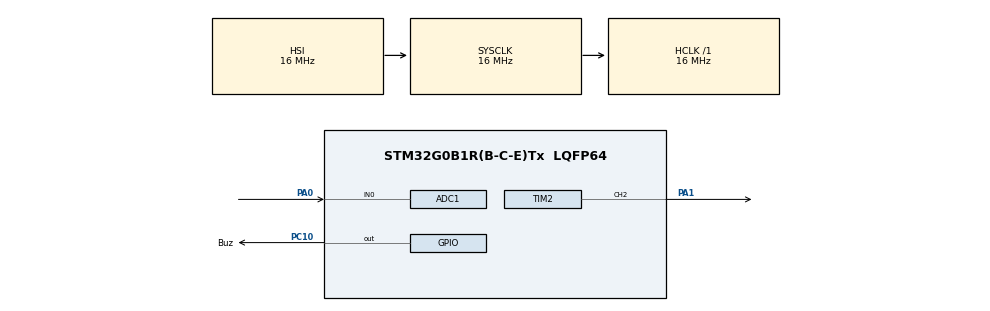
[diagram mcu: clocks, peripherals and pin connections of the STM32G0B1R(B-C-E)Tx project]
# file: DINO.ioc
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ADC1.Channel-0\#ChannelRegularConversion=ADC_CHANNEL_0
ADC1.ContinuousConvMode=ENABLE
ADC1.NbrOfConversionFlag=1
ADC1.Rank-0\#ChannelRegularConversion=1
ADC1.Resolution=ADC_RESOLUTION_6B
ADC1.SamplingTime-0\#ChannelRegularConversion=ADC_SAMPLINGTIME_COMMON_1
ADC1.SamplingTimeCommon1=ADC_SAMPLETIME_1CYCLE_5
ADC1.SamplingTimeCommon2=ADC_SAMPLETIME_1CYCLE_5
ADC1.SelectedChannel=ADC_CHANNEL_0
ADC1.master=1
Mcu.Family=STM32G0
Mcu.Name=STM32G0B1R(B-C-E)Tx
Mcu.Package=LQFP64
PA0.Mode=IN0
PA0.Signal=ADC1_IN0
PA1.Signal=S_TIM2_CH2
PA13.Mode=Serial_Wire
PA13.Signal=SYS_SWDIO
PA14-BOOT0.Mode=Serial_Wire
PA14-BOOT0.Signal=SYS_SWCLK
PC10.GPIO_Label=Buz
PC10.Signal=GPIO_Output
ProjectManager.HeapSize=0x200
ProjectManager.StackSize=0x400
ProjectManager.TargetToolchain=STM32CubeIDE
RCC.AHBFreq_Value=16000000
RCC.CortexFreq_Value=16000000
RCC.EXTERNAL_CLOCK_VALUE=48000
RCC.HCLKFreq_Value=16000000
RCC.HSE_VALUE=8000000
RCC.HSI48_VALUE=48000000
RCC.HSI_VALUE=16000000
RCC.LSE_VALUE=32768
RCC.SYSCLKFreq_VALUE=16000000
RCC.USBFreq_Value=48000000
RCC.VCOOutputFreq_Value=128000000
SH.S_TIM2_CH2.0=TIM2_CH2,PWM Generation2 CH2
TIM2.Channel-PWM\ Generation2\ CH2=TIM_CHANNEL_2
TIM2.Period=1000
TIM2.Prescaler=64
VP_SYS_VS_DBSignals.Mode=DisableDeadBatterySignals
VP_TIM2_VS_ClockSourceINT.Mode=Internal
board=custom

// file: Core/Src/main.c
/* USER CODE BEGIN Header */
/**
  ******************************************************************************
  * @file           : main.c
  * @brief          : Main program body
  ******************************************************************************
  * @attention
  *
  * Copyright (c) 2022 STMicroelectronics.
  * All rights reserved.
  *
  * This software is licensed under terms that can be found in the LICENSE file
  * in the root directory of this software component.
  * If no LICENSE file comes with this software, it is provided AS-IS.
  *
  ******************************************************************************
  */
/* USER CODE END Header */
#include "main.h"

/* USER CODE BEGIN Includes */
#include<stdint.h>
/* USER CODE END Includes */

/* USER CODE BEGIN PTD */
	uint32_t ldr = 0, timer = 0;
	uint8_t flag = 0;
/* USER CODE END PTD */

ADC_HandleTypeDef hadc1;

TIM_HandleTypeDef htim2;

void SystemClock_Config(void);
static void MX_GPIO_Init(void);
static void MX_ADC1_Init(void);
static void MX_TIM2_Init(void);

int main(void)
{

  /* MCU Configuration--------------------------------------------------------*/

  /* Reset of all peripherals, Initializes the Flash interface and the Systick. */
  HAL_Init();

  /* Configure the system clock */
  SystemClock_Config();

  /* Initialize all configured peripherals */
  MX_GPIO_Init();
  MX_ADC1_Init();
  MX_TIM2_Init();
  /* USER CODE BEGIN 2 */
  HAL_TIM_PWM_Start(&htim2, TIM_CHANNEL_2);//inicializa pwm que controla servo;
  TIM2->CCR2 = 65;

  /* USER CODE END 2 */

  /* Infinite loop */
  /* USER CODE BEGIN WHILE */
  while (1)
  {
    //leitura do LDR por ADC;
		HAL_ADC_Start(&hadc1);
		HAL_ADC_PollForConversion(&hadc1, 1);
		ldr = HAL_ADC_GetValue(&hadc1);

    //se identificar obstaculo ativa o servo;
		if (ldr > 8) {
			HAL_GPIO_WritePin(Buz_GPIO_Port, Buz_Pin, GPIO_PIN_SET);
			TIM2->CCR2 = 300;//define a posição do servo;
		}else{
			HAL_GPIO_WritePin(Buz_GPIO_Port, Buz_Pin, GPIO_PIN_RESET);
			TIM2->CCR2 = 500;//define a posição do servo;
		}

    /* USER CODE END WHILE */

    /* USER CODE BEGIN 3 */

	HAL_Delay(10);

  }
  /* USER CODE END 3 */
}

void SystemClock_Config(void)
{
  RCC_OscInitTypeDef RCC_OscInitStruct = {0};
  RCC_ClkInitTypeDef RCC_ClkInitStruct = {0};

  /** Configure the main internal regulator output voltage
  */
  HAL_PWREx_ControlVoltageScaling(PWR_REGULATOR_VOLTAGE_SCALE1);
  /** Initializes the RCC Oscillators according to the specified parameters
  * in the RCC_OscInitTypeDef structure.
  */
  RCC_OscInitStruct.OscillatorType = RCC_OSCILLATORTYPE_HSI;
  RCC_OscInitStruct.HSIState = RCC_HSI_ON;
  RCC_OscInitStruct.HSIDiv = RCC_HSI_DIV1;
  RCC_OscInitStruct.HSICalibrationValue = RCC_HSICALIBRATION_DEFAULT;
  RCC_OscInitStruct.PLL.PLLState = RCC_PLL_NONE;
  if (HAL_RCC_OscConfig(&RCC_OscInitStruct) != HAL_OK)
  {
    Error_Handler();
  }
  /** Initializes the CPU, AHB and APB buses clocks
  */
  RCC_ClkInitStruct.ClockType = RCC_CLOCKTYPE_HCLK|RCC_CLOCKTYPE_SYSCLK
                              |RCC_CLOCKTYPE_PCLK1;
  RCC_ClkInitStruct.SYSCLKSource = RCC_SYSCLKSOURCE_HSI;
  RCC_ClkInitStruct.AHBCLKDivider = RCC_SYSCLK_DIV1;
  RCC_ClkInitStruct.APB1CLKDivider = RCC_HCLK_DIV1;

  if (HAL_RCC_ClockConfig(&RCC_ClkInitStruct, FLASH_LATENCY_0) != HAL_OK)
  {
    Error_Handler();
  }
}

static void MX_ADC1_Init(void)
{

  ADC_ChannelConfTypeDef sConfig = {0};

  /** Configure the global features of the ADC (Clock, Resolution, Data Alignment and number of conversion)
  */
  hadc1.Instance = ADC1;
  hadc1.Init.ClockPrescaler = ADC_CLOCK_SYNC_PCLK_DIV2;
  hadc1.Init.Resolution = ADC_RESOLUTION_6B;
  hadc1.Init.DataAlign = ADC_DATAALIGN_RIGHT;
  hadc1.Init.ScanConvMode = ADC_SCAN_DISABLE;
  hadc1.Init.EOCSelection = ADC_EOC_SINGLE_CONV;
  hadc1.Init.LowPowerAutoWait = DISABLE;
  hadc1.Init.LowPowerAutoPowerOff = DISABLE;
  hadc1.Init.ContinuousConvMode = ENABLE;
  hadc1.Init.NbrOfConversion = 1;
  hadc1.Init.DiscontinuousConvMode = DISABLE;
  hadc1.Init.ExternalTrigConv = ADC_SOFTWARE_START;
  hadc1.Init.ExternalTrigConvEdge = ADC_EXTERNALTRIGCONVEDGE_NONE;
  hadc1.Init.DMAContinuousRequests = DISABLE;
  hadc1.Init.Overrun = ADC_OVR_DATA_PRESERVED;
  hadc1.Init.SamplingTimeCommon1 = ADC_SAMPLETIME_1CYCLE_5;
  hadc1.Init.SamplingTimeCommon2 = ADC_SAMPLETIME_1CYCLE_5;
  hadc1.Init.OversamplingMode = DISABLE;
  hadc1.Init.TriggerFrequencyMode = ADC_TRIGGER_FREQ_HIGH;
  if (HAL_ADC_Init(&hadc1) != HAL_OK)
  {
    Error_Handler();
  }
  /** Configure Regular Channel
  */
  sConfig.Channel = ADC_CHANNEL_0;
  sConfig.Rank = ADC_REGULAR_RANK_1;
  sConfig.SamplingTime = ADC_SAMPLINGTIME_COMMON_1;
  if (HAL_ADC_ConfigChannel(&hadc1, &sConfig) != HAL_OK)
  {
    Error_Handler();
  }

}

static void MX_TIM2_Init(void)
{

  TIM_ClockConfigTypeDef sClockSourceConfig = {0};
  TIM_MasterConfigTypeDef sMasterConfig = {0};
  TIM_OC_InitTypeDef sConfigOC = {0};

  htim2.Instance = TIM2;
  htim2.Init.Prescaler = 64;
  htim2.Init.CounterMode = TIM_COUNTERMODE_UP;
  htim2.Init.Period = 1000;
  htim2.Init.ClockDivision = TIM_CLOCKDIVISION_DIV1;
  htim2.Init.AutoReloadPreload = TIM_AUTORELOAD_PRELOAD_DISABLE;
  if (HAL_TIM_Base_Init(&htim2) != HAL_OK)
  {
    Error_Handler();
  }
  sClockSourceConfig.ClockSource = TIM_CLOCKSOURCE_INTERNAL;
  if (HAL_TIM_ConfigClockSource(&htim2, &sClockSourceConfig) != HAL_OK)
  {
    Error_Handler();
  }
  if (HAL_TIM_PWM_Init(&htim2) != HAL_OK)
  {
    Error_Handler();
  }
  sMasterConfig.MasterOutputTrigger = TIM_TRGO_RESET;
  sMasterConfig.MasterSlaveMode = TIM_MASTERSLAVEMODE_DISABLE;
  if (HAL_TIMEx_MasterConfigSynchronization(&htim2, &sMasterConfig) != HAL_OK)
  {
    Error_Handler();
  }
  sConfigOC.OCMode = TIM_OCMODE_PWM1;
  sConfigOC.Pulse = 0;
  sConfigOC.OCPolarity = TIM_OCPOLARITY_HIGH;
  sConfigOC.OCFastMode = TIM_OCFAST_DISABLE;
  if (HAL_TIM_PWM_ConfigChannel(&htim2, &sConfigOC, TIM_CHANNEL_2) != HAL_OK)
  {
    Error_Handler();
  }
  HAL_TIM_MspPostInit(&htim2);

}

static void MX_GPIO_Init(void)
{
  GPIO_InitTypeDef GPIO_InitStruct = {0};

  /* GPIO Ports Clock Enable */
  __HAL_RCC_GPIOA_CLK_ENABLE();
  __HAL_RCC_GPIOC_CLK_ENABLE();

  /*Configure GPIO pin Output Level */
  HAL_GPIO_WritePin(Buz_GPIO_Port, Buz_Pin, GPIO_PIN_RESET);

  /*Configure GPIO pin : Buz_Pin */
  GPIO_InitStruct.Pin = Buz_Pin;
  GPIO_InitStruct.Mode = GPIO_MODE_OUTPUT_PP;
  GPIO_InitStruct.Pull = GPIO_NOPULL;
  GPIO_InitStruct.Speed = GPIO_SPEED_FREQ_LOW;
  HAL_GPIO_Init(Buz_GPIO_Port, &GPIO_InitStruct);

}

void Error_Handler(void)
{
  __disable_irq();
  while (1)
  {
  }
}
